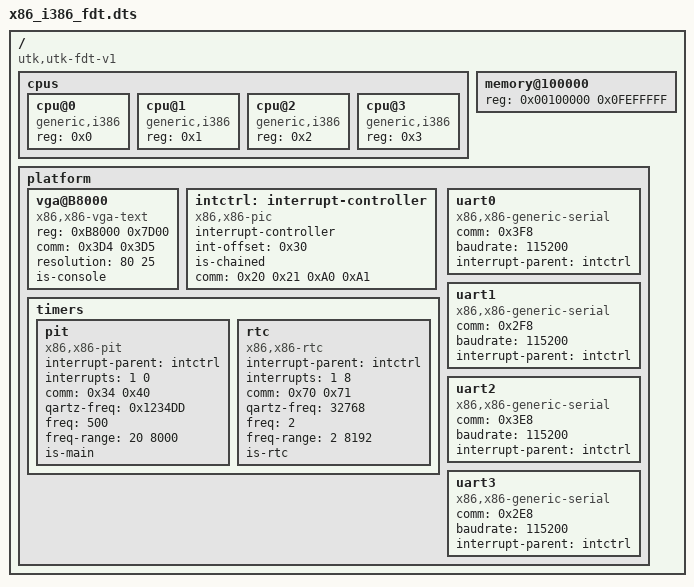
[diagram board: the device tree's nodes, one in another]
/dts-v1/;

/ {
    compatible = "utk,utk-fdt-v1";

    #address-cells = <1>;
    #size-cells = <1>;

    cpus {
        #address-cells = <1>;
        #size-cells = <0>;
        cpu@0 {
            compatible = "generic,i386";
            reg = <0x0>;
        };
        cpu@1 {
            compatible = "generic,i386";
            reg = <0x1>;
        };
        cpu@2 {
            compatible = "generic,i386";
            reg = <0x2>;
        };
        cpu@3 {
            compatible = "generic,i386";
            reg = <0x3>;
        };
    };

    memory@100000 {
        reg = <0x00100000 0x0FEFFFFF>; /* Available RAM, rest IO / lower mem */
    };

    platform {
        #address-cells = <1>;
        #size-cells = <1>;

        /* Place the VGA node first to get output on the VGA (eraly init) */
        vga@B8000 {
            compatible = "x86,x86-vga-text";
            reg = <0xB8000 0x7D00>;
            comm = <0x3D4 0x3D5>;
            resolution = <80 25>;
            is-console;
        };

        /* Interrupt controller must be placed before any device using
         * interrupts.
         */
        intctrl: interrupt-controller {
            compatible = "x86,x86-pic";
            interrupt-controller;
            #address-cells = <0>;
            #interrupt-cells = <2>;
            int-offset = <0x30>;
            is-chained;
            comm = <0x20 0x21 0xA0 0xA1>;
            status = "okay";
        };

        timers {
            pit {
                compatible = "x86,x86-pit";
                interrupt-parent = <&intctrl>;
                interrupts = <1 0>; /* 0: is IRQ; 1: IRQ line */
                comm = <0x34 0x40>;
                qartz-freq = <0x1234DD>;
                freq = <500>;
                freq-range = <20 8000>;
                is-main;
            };

            rtc {
                compatible = "x86,x86-rtc";
                interrupt-parent = <&intctrl>;
                interrupts = <1 8>; /* 0: is IRQ; 1: IRQ line */
                comm = <0x70 0x71>;
                qartz-freq = <32768>;
                freq = <2>;
                freq-range = <2 8192>;
                is-rtc;
            };
        };

        uart0 {
            compatible = "x86,x86-generic-serial";
            comm = <0x3F8>;
            baudrate = <115200>;
            interrupt-parent = <&intctrl>;
            // TODO: UARTdriver does not support interrupt for now
            //interrupts = <1 3>; /* 0: is IRQ; 1: IRQ line */
        };

        uart1 {
            compatible = "x86,x86-generic-serial";
            comm = <0x2F8>;
            baudrate = <115200>;
            interrupt-parent = <&intctrl>;
            // TODO: UARTdriver does not support interrupt for now
            //interrupts = <1 4>; /* 0: is IRQ; 1: IRQ line */
        };

        uart2 {
            compatible = "x86,x86-generic-serial";
            comm = <0x3E8>;
            baudrate = <115200>;
            interrupt-parent = <&intctrl>;
            // TODO: UARTdriver does not support interrupt for now
            //interrupts = <1 3>; /* 0: is IRQ; 1: IRQ line */
        };

        uart3 {
            compatible = "x86,x86-generic-serial";
            comm = <0x2E8>;
            baudrate = <115200>;
            interrupt-parent = <&intctrl>;
            // TODO: UARTdriver does not support interrupt for now
            // interrupts = <1 4>; /* 0: is IRQ; 1: IRQ line */
        };
    };
};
